AUTOSAR XML (schema 4-0-3)
standard types defined: uint8, Boolean, UInt16, UInt32, UInt8
package /AUTOSAR_Platform/DataConstrs
  range DC_Boolean: raw 0..1
  range DC_UInt16: raw 0..65535
  range DC_UInt8: raw 0..255
package /PATAC/Facility/DataTypes/Implementation
  compu method COMPU_Boolean: 0=FALSE, 1=TRUE
  unit NoUnit: factor-si-to-unit=1, offset-si-to-unit=0
package /PATAC/MSM/ComponentTypes
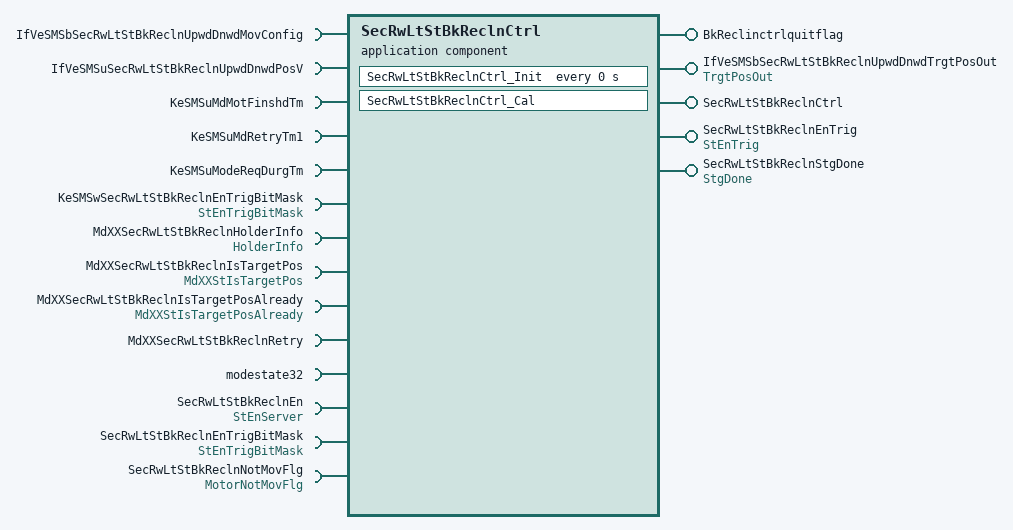
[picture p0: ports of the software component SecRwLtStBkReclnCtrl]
  application sw component type SecRwLtStBkReclnCtrl
    5 x provide port:
      BkReclinctrlquitflag: nonqueued-sender-com-spec{data-element=BkReclinctrlquitflag/Val, init-value=0}, provided-interface=BkReclinctrlquitflag
      IfVeSMSbSecRwLtStBkReclnUpwdDnwdTrgtPosOut: nonqueued-sender-com-spec{data-element=TrgtPosOut/Val, init-value=0}, provided-interface=TrgtPosOut
      SecRwLtStBkReclnCtrl: server-com-spec{operation=Cal, queue-length=1}, provided-interface=SecRwLtStBkReclnCtrl
      SecRwLtStBkReclnEnTrig: nonqueued-sender-com-spec{data-element=StEnTrig/Val, init-value=0}, provided-interface=StEnTrig
      SecRwLtStBkReclnStgDone: nonqueued-sender-com-spec{data-element=StgDone/Val, init-value=0}, provided-interface=StgDone
    14 x require port:
      IfVeSMSbSecRwLtStBkReclnUpwdDnwdMovConfig: nonqueued-receiver-com-spec{data-element=IfVeSMSbSecRwLtStBkReclnUpwdDnwdMovConfig/Val, filter=data-filter-type=ALWAYS, init-value=0}, required-interface=IfVeSMSbSecRwLtStBkReclnUpwdDnwdMovConfig
      IfVeSMSuSecRwLtStBkReclnUpwdDnwdPosV: nonqueued-receiver-com-spec{data-element=IfVeSMSuSecRwLtStBkReclnUpwdDnwdPosV/Val, filter=data-filter-type=ALWAYS, init-value=0}, required-interface=IfVeSMSuSecRwLtStBkReclnUpwdDnwdPosV
      KeSMSuMdMotFinshdTm: parameter-require-com-spec{init-value=0, parameter=KeSMSuMdMotFinshdTm/Val}, required-interface=KeSMSuMdMotFinshdTm
      KeSMSuMdRetryTm1: parameter-require-com-spec{init-value=0, parameter=KeSMSuMdRetryTm1/Val}, required-interface=KeSMSuMdRetryTm1
      KeSMSuModeReqDurgTm: parameter-require-com-spec{init-value=0, parameter=KeSMSuModeReqDurgTm/Val}, required-interface=KeSMSuModeReqDurgTm
      KeSMSwSecRwLtStBkReclnEnTrigBitMask: parameter-require-com-spec{init-value=6153, parameter=StEnTrigBitMask/Val}, required-interface=StEnTrigBitMask
      MdXXSecRwLtStBkReclnHolderInfo: nonqueued-receiver-com-spec{data-element=HolderInfo/Val, filter=data-filter-type=ALWAYS, init-value=0}, required-interface=HolderInfo
      MdXXSecRwLtStBkReclnIsTargetPos: nonqueued-receiver-com-spec{data-element=MdXXStIsTargetPos/Val, filter=data-filter-type=ALWAYS, init-value=0}, required-interface=MdXXStIsTargetPos
      MdXXSecRwLtStBkReclnIsTargetPosAlready: nonqueued-receiver-com-spec{data-element=MdXXStIsTargetPosAlready/Val, filter=data-filter-type=ALWAYS, init-value=0}, required-interface=MdXXStIsTargetPosAlready
      MdXXSecRwLtStBkReclnRetry: nonqueued-receiver-com-spec{data-element=MdXXSecRwLtStBkReclnRetry/Val, filter=data-filter-type=ALWAYS, init-value=0}, required-interface=MdXXSecRwLtStBkReclnRetry
      modestate32: nonqueued-receiver-com-spec{data-element=modestate32/Val, filter=data-filter-type=ALWAYS, init-value=0}, required-interface=modestate32
      SecRwLtStBkReclnEn: required-com-specs=[Clear, Get, Set], required-interface=StEnServer
      SecRwLtStBkReclnEnTrigBitMask: nonqueued-receiver-com-spec{data-element=StEnTrigBitMask/Val, filter=data-filter-type=ALWAYS, init-value=0}, required-interface=StEnTrigBitMask
      SecRwLtStBkReclnNotMovFlg: nonqueued-receiver-com-spec{data-element=MotorNotMovFlg/Val, filter=data-filter-type=ALWAYS, init-value=0}, required-interface=MotorNotMovFlg
    behavior SecRwLtStBkReclnCtrl_InternalBehavior
      operation invoked event OIT_SecRwLtStBkReclnCtrl_Cal_SecRwLtStBkReclnCtrl_Cal: start-on-event=SecRwLtStBkReclnCtrl_Cal, operation=SecRwLtStBkReclnCtrl.Cal
      timing event SecRwLtStBkReclnCtrl_InitEvent: start-on-event=SecRwLtStBkReclnCtrl_Init, period=0
      runnable SecRwLtStBkReclnCtrl_Cal
        data-receive-point-by-arguments:
          9 x access:
            REC_IfVeSMSbSecRwLtStBkReclnUpwdDnwdMovConfig_Val: accessed-variable=IfVeSMSbSecRwLtStBkReclnUpwdDnwdMovConfig.Val
            REC_IfVeSMSuSecRwLtStBkReclnUpwdDnwdPosV_Val: accessed-variable=IfVeSMSuSecRwLtStBkReclnUpwdDnwdPosV.Val
            REC_MdXXSecRwLtStBkReclnHolderInfo_Val: accessed-variable=MdXXSecRwLtStBkReclnHolderInfo.Val
            REC_MdXXSecRwLtStBkReclnIsTargetPos_Val: accessed-variable=MdXXSecRwLtStBkReclnIsTargetPos.Val
            REC_MdXXSecRwLtStBkReclnIsTargetPosAlready_Val: accessed-variable=MdXXSecRwLtStBkReclnIsTargetPosAlready.Val
            REC_MdXXSecRwLtStBkReclnRetry_Val: accessed-variable=MdXXSecRwLtStBkReclnRetry.Val
            REC_modestate32_Val: accessed-variable=modestate32.Val
            REC_SecRwLtStBkReclnEnTrigBitMask_Val: accessed-variable=SecRwLtStBkReclnEnTrigBitMask.Val
            REC_SecRwLtStBkReclnNotMovFlg_Val: accessed-variable=SecRwLtStBkReclnNotMovFlg.Val
        data-send-points:
          4 x access:
            SEND_BkReclinctrlquitflag_Val: accessed-variable=BkReclinctrlquitflag.Val
            SEND_IfVeSMSbSecRwLtStBkReclnUpwdDnwdTrgtPosOut_Val: accessed-variable=IfVeSMSbSecRwLtStBkReclnUpwdDnwdTrgtPosOut.Val
            SEND_SecRwLtStBkReclnEnTrig_Val: accessed-variable=SecRwLtStBkReclnEnTrig.Val
            SEND_SecRwLtStBkReclnStgDone_Val: accessed-variable=SecRwLtStBkReclnStgDone.Val
        4 x parameter access:
          PA_KeSMSuMdMotFinshdTm_Val: accessed-parameter=KeSMSuMdMotFinshdTm.Val
          PA_KeSMSuMdRetryTm1_Val: accessed-parameter=KeSMSuMdRetryTm1.Val
          PA_KeSMSuModeReqDurgTm_Val: accessed-parameter=KeSMSuModeReqDurgTm.Val
          PA_KeSMSwSecRwLtStBkReclnEnTrigBitMask_Val: accessed-parameter=KeSMSwSecRwLtStBkReclnEnTrigBitMask.Val
        sync call SC_SecRwLtStBkReclnEn_Get: operation=SecRwLtStBkReclnEn.Get, timeout=0
      runnable SecRwLtStBkReclnCtrl_Init
        4 x parameter access:
          PA_KeSMSuMdMotFinshdTm_Val: accessed-parameter=KeSMSuMdMotFinshdTm.Val
          PA_KeSMSuMdRetryTm1_Val: accessed-parameter=KeSMSuMdRetryTm1.Val
          PA_KeSMSuModeReqDurgTm_Val: accessed-parameter=KeSMSuModeReqDurgTm.Val
          PA_KeSMSwSecRwLtStBkReclnEnTrigBitMask_Val: accessed-parameter=KeSMSwSecRwLtStBkReclnEnTrigBitMask.Val
  swc implementation SecRwLtStBkReclnCtrl_Implementation: behavior=SecRwLtStBkReclnCtrl_InternalBehavior
    code-descriptors:
      code Default: artifact-descriptors=autosar-engineering-object={short-label=Default, category=SWSRC}
package /PATAC/MSM/ModeAdjust/CalPortInterface
  parameter interface KeSMSuMdMotFinshdTm
    parameter data prototype Val: sw-calibration-access=READ-WRITE, type=UInt16
  parameter interface KeSMSuModeReqDurgTm
    parameter data prototype Val: sw-calibration-access=READ-WRITE, type=UInt16
  parameter interface StEnTrigBitMask
    parameter data prototype Val: sw-calibration-access=READ-WRITE, type=UInt32
package /PATAC/MSM/ModeAdjust/Interfaces
  sender receiver interface IfVeSMSuSecRwLtStBkReclnUpwdDnwdPosV: invalidation-policy{data-element=IfVeSMSuSecRwLtStBkReclnUpwdDnwdPosV/Val, handle-invalid=DONT-INVALIDATE}
    data Val: type=Boolean
package /PATAC/MSM/ModeAdjust/PortInterface
  client server interface SecRwLtStBkReclnCtrl
    operation Cal
  client server interface StEnServer
    operation Clear
      arg data: type=UInt8, direction=IN, server-argument-impl-policy=USE-ARGUMENT-TYPE
    operation Get
      arg data: type=UInt32, direction=OUT, server-argument-impl-policy=USE-ARGUMENT-TYPE
    operation Set
      arg data: type=UInt8, direction=IN, server-argument-impl-policy=USE-ARGUMENT-TYPE
  11 x sender receiver interface:
    BkReclinctrlquitflag: invalidation-policy{data-element=BkReclinctrlquitflag/Val, handle-invalid=DONT-INVALIDATE}
      data Val: type=Boolean
    HolderInfo: invalidation-policy{data-element=HolderInfo/Val, handle-invalid=DONT-INVALIDATE}
      data Val: type=UInt32
    MdXXSecRwLtStBkReclnRetry: invalidation-policy{data-element=MdXXSecRwLtStBkReclnRetry/Val, handle-invalid=DONT-INVALIDATE}
      data Val: type=UInt32
    MdXXStIsTargetPos: invalidation-policy{data-element=MdXXStIsTargetPos/Val, handle-invalid=DONT-INVALIDATE}
      data Val: type=UInt32
    MdXXStIsTargetPosAlready: invalidation-policy{data-element=MdXXStIsTargetPosAlready/Val, handle-invalid=DONT-INVALIDATE}
      data Val: type=UInt32
    modestate32: invalidation-policy{data-element=modestate32/Val, handle-invalid=DONT-INVALIDATE}
      data Val: type=UInt32
    MotorNotMovFlg: invalidation-policy{data-element=MotorNotMovFlg/Val, handle-invalid=DONT-INVALIDATE}
      data Val: type=Boolean
    StEnTrig: invalidation-policy{data-element=StEnTrig/Val, handle-invalid=DONT-INVALIDATE}
      data Val: type=Boolean
    StEnTrigBitMask: invalidation-policy{data-element=StEnTrigBitMask/Val, handle-invalid=DONT-INVALIDATE}
      data Val: type=UInt32
    StgDone: invalidation-policy{data-element=StgDone/Val, handle-invalid=DONT-INVALIDATE}
      data Val: type=Boolean
    TrgtPosOut: invalidation-policy{data-element=TrgtPosOut/Val, handle-invalid=DONT-INVALIDATE}
      data Val: type=Boolean
package /PATAC/MSM/PortInterfaces
  parameter interface KeSMSuMdRetryTm1
    parameter data prototype Val: sw-calibration-access=READ-WRITE, type=UInt8
  sender receiver interface IfVeSMSbSecRwLtStBkReclnUpwdDnwdMovConfig: invalidation-policy{data-element=IfVeSMSbSecRwLtStBkReclnUpwdDnwdMovConfig/Val, handle-invalid=DONT-INVALIDATE}
    data Val: type=Boolean
